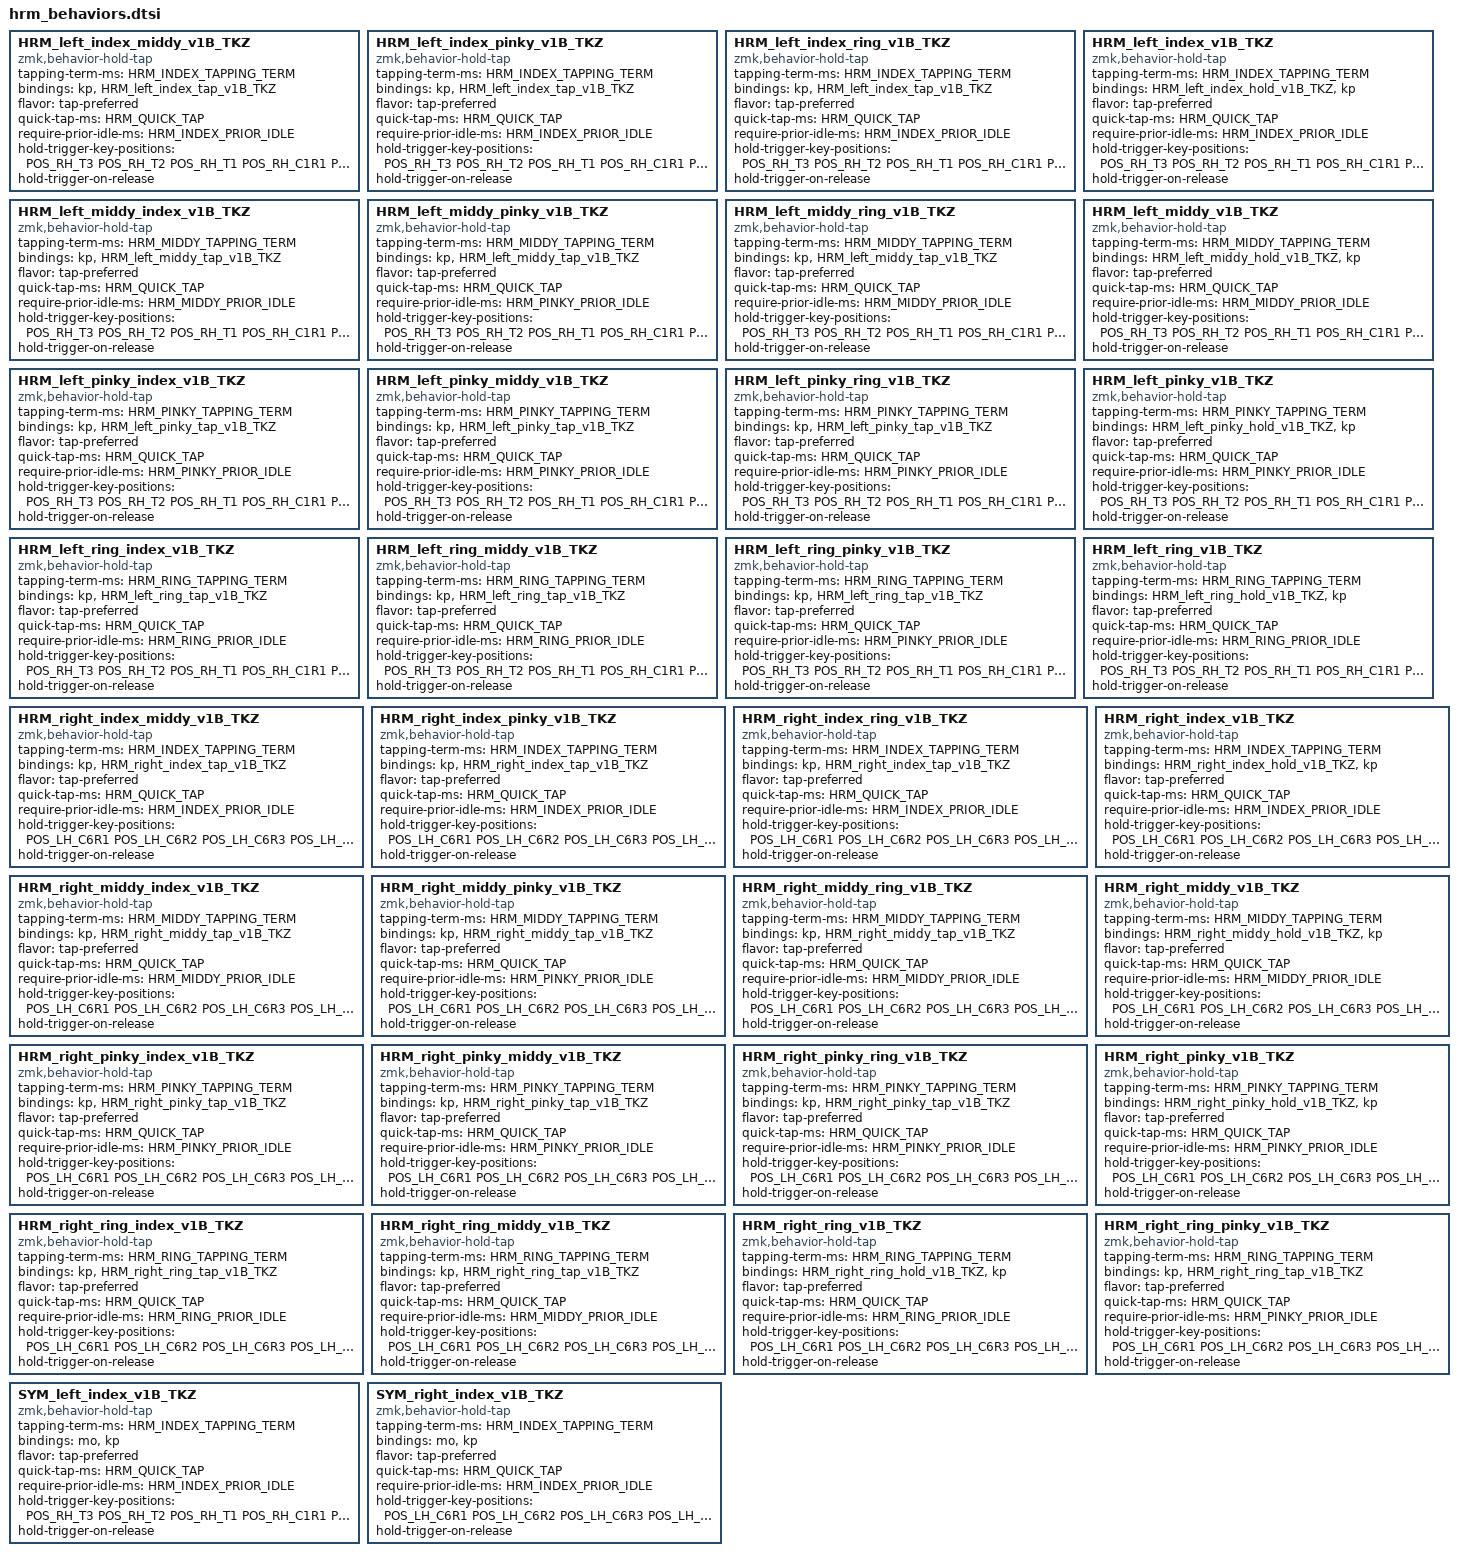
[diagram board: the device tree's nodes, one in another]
        // HRM_left_index_middy_bilateral -> &kp - &HRM_left_index_tap - TailorKey
        HRM_left_index_middy_v1B_TKZ: HRM_left_index_middy_v1B_TKZ {
            compatible = "zmk,behavior-hold-tap";
            #binding-cells = <2>;
            tapping-term-ms = <HRM_INDEX_TAPPING_TERM>;
            bindings = <&kp>, <&HRM_left_index_tap_v1B_TKZ>;
            flavor = "tap-preferred";
            quick-tap-ms = <HRM_QUICK_TAP>;
            require-prior-idle-ms = <HRM_INDEX_PRIOR_IDLE>;
            hold-trigger-key-positions = <POS_RH_T3 POS_RH_T2 POS_RH_T1 POS_RH_C1R1 POS_RH_C2R1 POS_RH_C3R1 POS_RH_C4R1 POS_RH_C5R1 POS_RH_C1R2 POS_RH_C2R2 POS_RH_C3R2 POS_RH_C4R2 POS_RH_C5R2 POS_RH_C1R3 POS_RH_C2R3 POS_RH_C3R3 POS_RH_C4R3 POS_RH_C5R3 POS_RH_C1R4 POS_RH_C2R4 POS_RH_C3R4 POS_RH_C4R4 POS_RH_C5R4 POS_RH_C2R5 POS_RH_C3R5 POS_RH_C4R5 POS_RH_C6R1 POS_RH_C6R2 POS_RH_C6R3 POS_RH_C6R4 POS_LH_T2 POS_LH_T3 POS_LH_T1>;
            hold-trigger-on-release;
        };

        // HRM_left_index_pinky_bilateral -> &kp - &HRM_left_index_tap - TailorKey
        HRM_left_index_pinky_v1B_TKZ: HRM_left_index_pinky_v1B_TKZ {
            compatible = "zmk,behavior-hold-tap";
            #binding-cells = <2>;
            tapping-term-ms = <HRM_INDEX_TAPPING_TERM>;
            bindings = <&kp>, <&HRM_left_index_tap_v1B_TKZ>;
            flavor = "tap-preferred";
            quick-tap-ms = <HRM_QUICK_TAP>;
            require-prior-idle-ms = <HRM_INDEX_PRIOR_IDLE>;
            hold-trigger-key-positions = <POS_RH_T3 POS_RH_T2 POS_RH_T1 POS_RH_C1R1 POS_RH_C2R1 POS_RH_C3R1 POS_RH_C4R1 POS_RH_C5R1 POS_RH_C1R2 POS_RH_C2R2 POS_RH_C3R2 POS_RH_C4R2 POS_RH_C5R2 POS_RH_C1R3 POS_RH_C2R3 POS_RH_C3R3 POS_RH_C4R3 POS_RH_C5R3 POS_RH_C1R4 POS_RH_C2R4 POS_RH_C3R4 POS_RH_C4R4 POS_RH_C5R4 POS_RH_C2R5 POS_RH_C3R5 POS_RH_C4R5 POS_RH_C6R1 POS_RH_C6R2 POS_RH_C6R3 POS_RH_C6R4 POS_LH_T2 POS_LH_T3 POS_LH_T1>;
            hold-trigger-on-release;
        };

        // HRM_left_index_ring_bilateral -> &kp - &HRM_left_index_tap - TailorKey
        HRM_left_index_ring_v1B_TKZ: HRM_left_index_ring_v1B_TKZ {
            compatible = "zmk,behavior-hold-tap";
            #binding-cells = <2>;
            tapping-term-ms = <HRM_INDEX_TAPPING_TERM>;
            bindings = <&kp>, <&HRM_left_index_tap_v1B_TKZ>;
            flavor = "tap-preferred";
            quick-tap-ms = <HRM_QUICK_TAP>;
            require-prior-idle-ms = <HRM_INDEX_PRIOR_IDLE>;
            hold-trigger-key-positions = <POS_RH_T3 POS_RH_T2 POS_RH_T1 POS_RH_C1R1 POS_RH_C2R1 POS_RH_C3R1 POS_RH_C4R1 POS_RH_C5R1 POS_RH_C1R2 POS_RH_C2R2 POS_RH_C3R2 POS_RH_C4R2 POS_RH_C5R2 POS_RH_C1R3 POS_RH_C2R3 POS_RH_C3R3 POS_RH_C4R3 POS_RH_C5R3 POS_RH_C1R4 POS_RH_C2R4 POS_RH_C3R4 POS_RH_C4R4 POS_RH_C5R4 POS_RH_C2R5 POS_RH_C3R5 POS_RH_C4R5 POS_RH_C6R1 POS_RH_C6R2 POS_RH_C6R3 POS_RH_C6R4 POS_LH_T2 POS_LH_T3 POS_LH_T1>;
            hold-trigger-on-release;
        };

        // HRM_left_index_bilateral -> &HRM_left_index_hold -> &kp - TailorKey
        HRM_left_index_v1B_TKZ: HRM_left_index_v1B_TKZ {
            compatible = "zmk,behavior-hold-tap";
            #binding-cells = <2>;
            tapping-term-ms = <HRM_INDEX_TAPPING_TERM>;
            bindings = <&HRM_left_index_hold_v1B_TKZ>, <&kp>;
            flavor = "tap-preferred";
            quick-tap-ms = <HRM_QUICK_TAP>;
            require-prior-idle-ms = <HRM_INDEX_PRIOR_IDLE>;
            hold-trigger-key-positions = <POS_RH_T3 POS_RH_T2 POS_RH_T1 POS_RH_C1R1 POS_RH_C2R1 POS_RH_C3R1 POS_RH_C4R1 POS_RH_C5R1 POS_RH_C1R2 POS_RH_C2R2 POS_RH_C3R2 POS_RH_C4R2 POS_RH_C5R2 POS_RH_C1R3 POS_RH_C2R3 POS_RH_C3R3 POS_RH_C4R3 POS_RH_C5R3 POS_RH_C1R4 POS_RH_C2R4 POS_RH_C3R4 POS_RH_C4R4 POS_RH_C5R4 POS_RH_C2R5 POS_RH_C3R5 POS_RH_C4R5 POS_RH_C6R1 POS_RH_C6R2 POS_RH_C6R3 POS_RH_C6R4 POS_LH_T2 POS_LH_T3 POS_LH_T1>;
            hold-trigger-on-release;
        };

        // HRM_left_middy_index_bilateral  -> &kp ->&HRM_left_middy_tap - TailorKey
        HRM_left_middy_index_v1B_TKZ: HRM_left_middy_index_v1B_TKZ {
            compatible = "zmk,behavior-hold-tap";
            #binding-cells = <2>;
            tapping-term-ms = <HRM_MIDDY_TAPPING_TERM>;
            bindings = <&kp>, <&HRM_left_middy_tap_v1B_TKZ>;
            flavor = "tap-preferred";
            quick-tap-ms = <HRM_QUICK_TAP>;
            require-prior-idle-ms = <HRM_MIDDY_PRIOR_IDLE>;
            hold-trigger-key-positions = <POS_RH_T3 POS_RH_T2 POS_RH_T1 POS_RH_C1R1 POS_RH_C2R1 POS_RH_C3R1 POS_RH_C4R1 POS_RH_C5R1 POS_RH_C1R2 POS_RH_C2R2 POS_RH_C3R2 POS_RH_C4R2 POS_RH_C5R2 POS_RH_C1R3 POS_RH_C2R3 POS_RH_C3R3 POS_RH_C4R3 POS_RH_C5R3 POS_RH_C1R4 POS_RH_C2R4 POS_RH_C3R4 POS_RH_C4R4 POS_RH_C5R4 POS_RH_C2R5 POS_RH_C3R5 POS_RH_C4R5 POS_RH_C6R1 POS_RH_C6R2 POS_RH_C6R3 POS_RH_C6R4 POS_LH_T2 POS_LH_T3 POS_LH_T1>;
            hold-trigger-on-release;
        };

        // HRM_left_middy_pinky_bilateral -> &kp - &HRM_left_pinky_tap - TailorKey
        HRM_left_middy_pinky_v1B_TKZ: HRM_left_middy_pinky_v1B_TKZ {
            compatible = "zmk,behavior-hold-tap";
            #binding-cells = <2>;
            tapping-term-ms = <HRM_MIDDY_TAPPING_TERM>;
            bindings = <&kp>, <&HRM_left_middy_tap_v1B_TKZ>;
            flavor = "tap-preferred";
            quick-tap-ms = <HRM_QUICK_TAP>;
            require-prior-idle-ms = <HRM_PINKY_PRIOR_IDLE>;
            hold-trigger-key-positions = <POS_RH_T3 POS_RH_T2 POS_RH_T1 POS_RH_C1R1 POS_RH_C2R1 POS_RH_C3R1 POS_RH_C4R1 POS_RH_C5R1 POS_RH_C1R2 POS_RH_C2R2 POS_RH_C3R2 POS_RH_C4R2 POS_RH_C5R2 POS_RH_C1R3 POS_RH_C2R3 POS_RH_C3R3 POS_RH_C4R3 POS_RH_C5R3 POS_RH_C1R4 POS_RH_C2R4 POS_RH_C3R4 POS_RH_C4R4 POS_RH_C5R4 POS_RH_C2R5 POS_RH_C3R5 POS_RH_C4R5 POS_RH_C6R1 POS_RH_C6R2 POS_RH_C6R3 POS_RH_C6R4 POS_LH_T2 POS_LH_T3 POS_LH_T1>;
            hold-trigger-on-release;
        };

        // HRM_left_middy_ring_bilateral -> &kp - &HRM_left_middy_tap - TailorKey
        HRM_left_middy_ring_v1B_TKZ: HRM_left_middy_ring_v1B_TKZ {
            compatible = "zmk,behavior-hold-tap";
            #binding-cells = <2>;
            tapping-term-ms = <HRM_MIDDY_TAPPING_TERM>;
            bindings = <&kp>, <&HRM_left_middy_tap_v1B_TKZ>;
            flavor = "tap-preferred";
            quick-tap-ms = <HRM_QUICK_TAP>;
            require-prior-idle-ms = <HRM_MIDDY_PRIOR_IDLE>;
            hold-trigger-key-positions = <POS_RH_T3 POS_RH_T2 POS_RH_T1 POS_RH_C1R1 POS_RH_C2R1 POS_RH_C3R1 POS_RH_C4R1 POS_RH_C5R1 POS_RH_C1R2 POS_RH_C2R2 POS_RH_C3R2 POS_RH_C4R2 POS_RH_C5R2 POS_RH_C1R3 POS_RH_C2R3 POS_RH_C3R3 POS_RH_C4R3 POS_RH_C5R3 POS_RH_C1R4 POS_RH_C2R4 POS_RH_C3R4 POS_RH_C4R4 POS_RH_C5R4 POS_RH_C2R5 POS_RH_C3R5 POS_RH_C4R5 POS_RH_C6R1 POS_RH_C6R2 POS_RH_C6R3 POS_RH_C6R4 POS_LH_T2 POS_LH_T3 POS_LH_T1>;
            hold-trigger-on-release;
        };

        // HRM_left_middy_bilateral -> &HRM_left_index_hold -> &kp - TailorKey
        HRM_left_middy_v1B_TKZ: HRM_left_middy_v1B_TKZ {
            compatible = "zmk,behavior-hold-tap";
            #binding-cells = <2>;
            tapping-term-ms = <HRM_MIDDY_TAPPING_TERM>;
            bindings = <&HRM_left_middy_hold_v1B_TKZ>, <&kp>;
            flavor = "tap-preferred";
            quick-tap-ms = <HRM_QUICK_TAP>;
            require-prior-idle-ms = <HRM_MIDDY_PRIOR_IDLE>;
            hold-trigger-key-positions = <POS_RH_T3 POS_RH_T2 POS_RH_T1 POS_RH_C1R1 POS_RH_C2R1 POS_RH_C3R1 POS_RH_C4R1 POS_RH_C5R1 POS_RH_C1R2 POS_RH_C2R2 POS_RH_C3R2 POS_RH_C4R2 POS_RH_C5R2 POS_RH_C1R3 POS_RH_C2R3 POS_RH_C3R3 POS_RH_C4R3 POS_RH_C5R3 POS_RH_C1R4 POS_RH_C2R4 POS_RH_C3R4 POS_RH_C4R4 POS_RH_C5R4 POS_RH_C2R5 POS_RH_C3R5 POS_RH_C4R5 POS_RH_C6R1 POS_RH_C6R2 POS_RH_C6R3 POS_RH_C6R4 POS_LH_T2 POS_LH_T3 POS_LH_T1>;
            hold-trigger-on-release;
        };

        // HRM_left_pinky_index_bilateral  -> &kp ->&HRM_left_pinky_tap - TailorKey
        HRM_left_pinky_index_v1B_TKZ: HRM_left_pinky_index_v1B_TKZ {
            compatible = "zmk,behavior-hold-tap";
            #binding-cells = <2>;
            tapping-term-ms = <HRM_PINKY_TAPPING_TERM>;
            bindings = <&kp>, <&HRM_left_pinky_tap_v1B_TKZ>;
            flavor = "tap-preferred";
            quick-tap-ms = <HRM_QUICK_TAP>;
            require-prior-idle-ms = <HRM_PINKY_PRIOR_IDLE>;
            hold-trigger-key-positions = <POS_RH_T3 POS_RH_T2 POS_RH_T1 POS_RH_C1R1 POS_RH_C2R1 POS_RH_C3R1 POS_RH_C4R1 POS_RH_C5R1 POS_RH_C1R2 POS_RH_C2R2 POS_RH_C3R2 POS_RH_C4R2 POS_RH_C5R2 POS_RH_C1R3 POS_RH_C2R3 POS_RH_C3R3 POS_RH_C4R3 POS_RH_C5R3 POS_RH_C1R4 POS_RH_C2R4 POS_RH_C3R4 POS_RH_C4R4 POS_RH_C5R4 POS_RH_C2R5 POS_RH_C3R5 POS_RH_C4R5 POS_RH_C6R1 POS_RH_C6R2 POS_RH_C6R3 POS_RH_C6R4 POS_LH_T2 POS_LH_T3 POS_LH_T1>;
            hold-trigger-on-release;
        };

        // HRM_left_pinky_middy_bilateral -> &kp - &HRM_left_pinky_tap - TailorKey
        HRM_left_pinky_middy_v1B_TKZ: HRM_left_pinky_middy_v1B_TKZ {
            compatible = "zmk,behavior-hold-tap";
            #binding-cells = <2>;
            tapping-term-ms = <HRM_PINKY_TAPPING_TERM>;
            bindings = <&kp>, <&HRM_left_pinky_tap_v1B_TKZ>;
            flavor = "tap-preferred";
            quick-tap-ms = <HRM_QUICK_TAP>;
            require-prior-idle-ms = <HRM_PINKY_PRIOR_IDLE>;
            hold-trigger-key-positions = <POS_RH_T3 POS_RH_T2 POS_RH_T1 POS_RH_C1R1 POS_RH_C2R1 POS_RH_C3R1 POS_RH_C4R1 POS_RH_C5R1 POS_RH_C1R2 POS_RH_C2R2 POS_RH_C3R2 POS_RH_C4R2 POS_RH_C5R2 POS_RH_C1R3 POS_RH_C2R3 POS_RH_C3R3 POS_RH_C4R3 POS_RH_C5R3 POS_RH_C1R4 POS_RH_C2R4 POS_RH_C3R4 POS_RH_C4R4 POS_RH_C5R4 POS_RH_C2R5 POS_RH_C3R5 POS_RH_C4R5 POS_RH_C6R1 POS_RH_C6R2 POS_RH_C6R3 POS_RH_C6R4 POS_LH_T2 POS_LH_T3 POS_LH_T1>;
            hold-trigger-on-release;
        };

        // HRM_left_pinky_ring_bilateral -> &kp - &HRM_left_pinky_tap - TailorKey
        HRM_left_pinky_ring_v1B_TKZ: HRM_left_pinky_ring_v1B_TKZ {
            compatible = "zmk,behavior-hold-tap";
            #binding-cells = <2>;
            tapping-term-ms = <HRM_PINKY_TAPPING_TERM>;
            bindings = <&kp>, <&HRM_left_pinky_tap_v1B_TKZ>;
            flavor = "tap-preferred";
            quick-tap-ms = <HRM_QUICK_TAP>;
            require-prior-idle-ms = <HRM_PINKY_PRIOR_IDLE>;
            hold-trigger-key-positions = <POS_RH_T3 POS_RH_T2 POS_RH_T1 POS_RH_C1R1 POS_RH_C2R1 POS_RH_C3R1 POS_RH_C4R1 POS_RH_C5R1 POS_RH_C1R2 POS_RH_C2R2 POS_RH_C3R2 POS_RH_C4R2 POS_RH_C5R2 POS_RH_C1R3 POS_RH_C2R3 POS_RH_C3R3 POS_RH_C4R3 POS_RH_C5R3 POS_RH_C1R4 POS_RH_C2R4 POS_RH_C3R4 POS_RH_C4R4 POS_RH_C5R4 POS_RH_C2R5 POS_RH_C3R5 POS_RH_C4R5 POS_RH_C6R1 POS_RH_C6R2 POS_RH_C6R3 POS_RH_C6R4 POS_LH_T2 POS_LH_T3 POS_LH_T1>;
            hold-trigger-on-release;
        };

        // HRM_left_pinky_bilateral  - &HRM_left_pinky_hold -> &kp - TailorKey
        HRM_left_pinky_v1B_TKZ: HRM_left_pinky_v1B_TKZ {
            compatible = "zmk,behavior-hold-tap";
            #binding-cells = <2>;
            tapping-term-ms = <HRM_PINKY_TAPPING_TERM>;
            bindings = <&HRM_left_pinky_hold_v1B_TKZ>, <&kp>;
            flavor = "tap-preferred";
            quick-tap-ms = <HRM_QUICK_TAP>;
            require-prior-idle-ms = <HRM_PINKY_PRIOR_IDLE>;
            hold-trigger-key-positions = <POS_RH_T3 POS_RH_T2 POS_RH_T1 POS_RH_C1R1 POS_RH_C2R1 POS_RH_C3R1 POS_RH_C4R1 POS_RH_C5R1 POS_RH_C1R2 POS_RH_C2R2 POS_RH_C3R2 POS_RH_C4R2 POS_RH_C5R2 POS_RH_C1R3 POS_RH_C2R3 POS_RH_C3R3 POS_RH_C4R3 POS_RH_C5R3 POS_RH_C1R4 POS_RH_C2R4 POS_RH_C3R4 POS_RH_C4R4 POS_RH_C5R4 POS_RH_C2R5 POS_RH_C3R5 POS_RH_C4R5 POS_RH_C6R1 POS_RH_C6R2 POS_RH_C6R3 POS_RH_C6R4 POS_LH_T2 POS_LH_T3 POS_LH_T1>;
            hold-trigger-on-release;
        };

        // HRM_left_ring_index_bilateral  -> &kp ->&HRM_left_ring_tap - TailorKey
        HRM_left_ring_index_v1B_TKZ: HRM_left_ring_index_v1B_TKZ {
            compatible = "zmk,behavior-hold-tap";
            #binding-cells = <2>;
            tapping-term-ms = <HRM_RING_TAPPING_TERM>;
            bindings = <&kp>, <&HRM_left_ring_tap_v1B_TKZ>;
            flavor = "tap-preferred";
            quick-tap-ms = <HRM_QUICK_TAP>;
            require-prior-idle-ms = <HRM_RING_PRIOR_IDLE>;
            hold-trigger-key-positions = <POS_RH_T3 POS_RH_T2 POS_RH_T1 POS_RH_C1R1 POS_RH_C2R1 POS_RH_C3R1 POS_RH_C4R1 POS_RH_C5R1 POS_RH_C1R2 POS_RH_C2R2 POS_RH_C3R2 POS_RH_C4R2 POS_RH_C5R2 POS_RH_C1R3 POS_RH_C2R3 POS_RH_C3R3 POS_RH_C4R3 POS_RH_C5R3 POS_RH_C1R4 POS_RH_C2R4 POS_RH_C3R4 POS_RH_C4R4 POS_RH_C5R4 POS_RH_C2R5 POS_RH_C3R5 POS_RH_C4R5 POS_RH_C6R1 POS_RH_C6R2 POS_RH_C6R3 POS_RH_C6R4 POS_LH_T2 POS_LH_T3 POS_LH_T1>;
            hold-trigger-on-release;
        };

        // HRM_left_ring_middy_bilateral -> &kp - &HRM_left_ring_tap - TailorKey
        HRM_left_ring_middy_v1B_TKZ: HRM_left_ring_middy_v1B_TKZ {
            compatible = "zmk,behavior-hold-tap";
            #binding-cells = <2>;
            tapping-term-ms = <HRM_RING_TAPPING_TERM>;
            bindings = <&kp>, <&HRM_left_ring_tap_v1B_TKZ>;
            flavor = "tap-preferred";
            quick-tap-ms = <HRM_QUICK_TAP>;
            require-prior-idle-ms = <HRM_RING_PRIOR_IDLE>;
            hold-trigger-key-positions = <POS_RH_T3 POS_RH_T2 POS_RH_T1 POS_RH_C1R1 POS_RH_C2R1 POS_RH_C3R1 POS_RH_C4R1 POS_RH_C5R1 POS_RH_C1R2 POS_RH_C2R2 POS_RH_C3R2 POS_RH_C4R2 POS_RH_C5R2 POS_RH_C1R3 POS_RH_C2R3 POS_RH_C3R3 POS_RH_C4R3 POS_RH_C5R3 POS_RH_C1R4 POS_RH_C2R4 POS_RH_C3R4 POS_RH_C4R4 POS_RH_C5R4 POS_RH_C2R5 POS_RH_C3R5 POS_RH_C4R5 POS_RH_C6R1 POS_RH_C6R2 POS_RH_C6R3 POS_RH_C6R4 POS_LH_T2 POS_LH_T3 POS_LH_T1>;
            hold-trigger-on-release;
        };

        // HRM_left_ring_pinky_bilateral -> &kp - &HRM_left_ring_tap - TailorKey
        HRM_left_ring_pinky_v1B_TKZ: HRM_left_ring_pinky_v1B_TKZ {
            compatible = "zmk,behavior-hold-tap";
            #binding-cells = <2>;
            tapping-term-ms = <HRM_RING_TAPPING_TERM>;
            bindings = <&kp>, <&HRM_left_ring_tap_v1B_TKZ>;
            flavor = "tap-preferred";
            quick-tap-ms = <HRM_QUICK_TAP>;
            require-prior-idle-ms = <HRM_PINKY_PRIOR_IDLE>;
            hold-trigger-key-positions = <POS_RH_T3 POS_RH_T2 POS_RH_T1 POS_RH_C1R1 POS_RH_C2R1 POS_RH_C3R1 POS_RH_C4R1 POS_RH_C5R1 POS_RH_C1R2 POS_RH_C2R2 POS_RH_C3R2 POS_RH_C4R2 POS_RH_C5R2 POS_RH_C1R3 POS_RH_C2R3 POS_RH_C3R3 POS_RH_C4R3 POS_RH_C5R3 POS_RH_C1R4 POS_RH_C2R4 POS_RH_C3R4 POS_RH_C4R4 POS_RH_C5R4 POS_RH_C2R5 POS_RH_C3R5 POS_RH_C4R5 POS_RH_C6R1 POS_RH_C6R2 POS_RH_C6R3 POS_RH_C6R4 POS_LH_T2 POS_LH_T3 POS_LH_T1>;
            hold-trigger-on-release;
        };

        // HRM_left_ring_bilateral  - &HRM_left_ring_hold -> &kp - TailorKey
        HRM_left_ring_v1B_TKZ: HRM_left_ring_v1B_TKZ {
            compatible = "zmk,behavior-hold-tap";
            #binding-cells = <2>;
            tapping-term-ms = <HRM_RING_TAPPING_TERM>;
            bindings = <&HRM_left_ring_hold_v1B_TKZ>, <&kp>;
            flavor = "tap-preferred";
            quick-tap-ms = <HRM_QUICK_TAP>;
            require-prior-idle-ms = <HRM_RING_PRIOR_IDLE>;
            hold-trigger-key-positions = <POS_RH_T3 POS_RH_T2 POS_RH_T1 POS_RH_C1R1 POS_RH_C2R1 POS_RH_C3R1 POS_RH_C4R1 POS_RH_C5R1 POS_RH_C1R2 POS_RH_C2R2 POS_RH_C3R2 POS_RH_C4R2 POS_RH_C5R2 POS_RH_C1R3 POS_RH_C2R3 POS_RH_C3R3 POS_RH_C4R3 POS_RH_C5R3 POS_RH_C1R4 POS_RH_C2R4 POS_RH_C3R4 POS_RH_C4R4 POS_RH_C5R4 POS_RH_C2R5 POS_RH_C3R5 POS_RH_C4R5 POS_RH_C6R1 POS_RH_C6R2 POS_RH_C6R3 POS_RH_C6R4 POS_LH_T2 POS_LH_T3 POS_LH_T1>;
            hold-trigger-on-release;
        };

        // HRM_right_index_middy_bilateral -> &kp - &HRM_right_index_tap - TailorKey
        HRM_right_index_middy_v1B_TKZ: HRM_right_index_middy_v1B_TKZ {
            compatible = "zmk,behavior-hold-tap";
            #binding-cells = <2>;
            tapping-term-ms = <HRM_INDEX_TAPPING_TERM>;
            bindings = <&kp>, <&HRM_right_index_tap_v1B_TKZ>;
            flavor = "tap-preferred";
            quick-tap-ms = <HRM_QUICK_TAP>;
            require-prior-idle-ms = <HRM_INDEX_PRIOR_IDLE>;
            hold-trigger-key-positions = <POS_LH_C6R1 POS_LH_C6R2 POS_LH_C6R3 POS_LH_C6R4 POS_LH_C5R4 POS_LH_C5R3 POS_LH_C5R2 POS_LH_C4R1 POS_LH_C5R1 POS_LH_C4R2 POS_LH_C4R3 POS_LH_C4R4 POS_LH_C4R5 POS_LH_C3R5 POS_LH_C3R4 POS_LH_C3R3 POS_LH_C3R2 POS_LH_C3R1 POS_LH_C2R1 POS_LH_C1R1 POS_LH_C1R2 POS_LH_C2R2 POS_LH_C2R3 POS_LH_C1R3 POS_LH_C1R4 POS_LH_C2R4 POS_LH_C2R5 POS_LH_T3 POS_LH_T2 POS_LH_T1 POS_RH_T1 POS_RH_T2 POS_RH_T3>;
            hold-trigger-on-release;
        };

        // HRM_right_index_pinky_bilateral -> &kp - &HRM_right_index_tap - TailorKey
        HRM_right_index_pinky_v1B_TKZ: HRM_right_index_pinky_v1B_TKZ {
            compatible = "zmk,behavior-hold-tap";
            #binding-cells = <2>;
            tapping-term-ms = <HRM_INDEX_TAPPING_TERM>;
            bindings = <&kp>, <&HRM_right_index_tap_v1B_TKZ>;
            flavor = "tap-preferred";
            quick-tap-ms = <HRM_QUICK_TAP>;
            require-prior-idle-ms = <HRM_INDEX_PRIOR_IDLE>;
            hold-trigger-key-positions = <POS_LH_C6R1 POS_LH_C6R2 POS_LH_C6R3 POS_LH_C6R4 POS_LH_C5R4 POS_LH_C5R3 POS_LH_C5R2 POS_LH_C4R1 POS_LH_C5R1 POS_LH_C4R2 POS_LH_C4R3 POS_LH_C4R4 POS_LH_C4R5 POS_LH_C3R5 POS_LH_C3R4 POS_LH_C3R3 POS_LH_C3R2 POS_LH_C3R1 POS_LH_C2R1 POS_LH_C1R1 POS_LH_C1R2 POS_LH_C2R2 POS_LH_C2R3 POS_LH_C1R3 POS_LH_C1R4 POS_LH_C2R4 POS_LH_C2R5 POS_LH_T3 POS_LH_T2 POS_LH_T1 POS_RH_T1 POS_RH_T2 POS_RH_T3>;
            hold-trigger-on-release;
        };

        // HRM_right_index_ring_bilateral -> &kp - &HRM_right_index_tap - TailorKey
        HRM_right_index_ring_v1B_TKZ: HRM_right_index_ring_v1B_TKZ {
            compatible = "zmk,behavior-hold-tap";
            #binding-cells = <2>;
            tapping-term-ms = <HRM_INDEX_TAPPING_TERM>;
            bindings = <&kp>, <&HRM_right_index_tap_v1B_TKZ>;
            flavor = "tap-preferred";
            quick-tap-ms = <HRM_QUICK_TAP>;
            require-prior-idle-ms = <HRM_INDEX_PRIOR_IDLE>;
            hold-trigger-key-positions = <POS_LH_C6R1 POS_LH_C6R2 POS_LH_C6R3 POS_LH_C6R4 POS_LH_C5R4 POS_LH_C5R3 POS_LH_C5R2 POS_LH_C4R1 POS_LH_C5R1 POS_LH_C4R2 POS_LH_C4R3 POS_LH_C4R4 POS_LH_C4R5 POS_LH_C3R5 POS_LH_C3R4 POS_LH_C3R3 POS_LH_C3R2 POS_LH_C3R1 POS_LH_C2R1 POS_LH_C1R1 POS_LH_C1R2 POS_LH_C2R2 POS_LH_C2R3 POS_LH_C1R3 POS_LH_C1R4 POS_LH_C2R4 POS_LH_C2R5 POS_LH_T3 POS_LH_T2 POS_LH_T1 POS_RH_T1 POS_RH_T2 POS_RH_T3>;
            hold-trigger-on-release;
        };

        // HRM_right_index_bilateral -> &HRM_right_index_hold -> &kp - TailorKey
        HRM_right_index_v1B_TKZ: HRM_right_index_v1B_TKZ {
            compatible = "zmk,behavior-hold-tap";
            #binding-cells = <2>;
            tapping-term-ms = <HRM_INDEX_TAPPING_TERM>;
            bindings = <&HRM_right_index_hold_v1B_TKZ>, <&kp>;
            flavor = "tap-preferred";
            quick-tap-ms = <HRM_QUICK_TAP>;
            require-prior-idle-ms = <HRM_INDEX_PRIOR_IDLE>;
            hold-trigger-key-positions = <POS_LH_C6R1 POS_LH_C6R2 POS_LH_C6R3 POS_LH_C6R4 POS_LH_C5R4 POS_LH_C5R3 POS_LH_C5R2 POS_LH_C4R1 POS_LH_C5R1 POS_LH_C4R2 POS_LH_C4R3 POS_LH_C4R4 POS_LH_C4R5 POS_LH_C3R5 POS_LH_C3R4 POS_LH_C3R3 POS_LH_C3R2 POS_LH_C3R1 POS_LH_C2R1 POS_LH_C1R1 POS_LH_C1R2 POS_LH_C2R2 POS_LH_C2R3 POS_LH_C1R3 POS_LH_C1R4 POS_LH_C2R4 POS_LH_C2R5 POS_LH_T3 POS_LH_T2 POS_LH_T1 POS_RH_T1 POS_RH_T2 POS_RH_T3>;
            hold-trigger-on-release;
        };

        // HRM_right_middy_index_bilateral  -> &kp ->&HRM_right_middy_tap - TailorKey
        HRM_right_middy_index_v1B_TKZ: HRM_right_middy_index_v1B_TKZ {
            compatible = "zmk,behavior-hold-tap";
            #binding-cells = <2>;
            tapping-term-ms = <HRM_MIDDY_TAPPING_TERM>;
            bindings = <&kp>, <&HRM_right_middy_tap_v1B_TKZ>;
            flavor = "tap-preferred";
            quick-tap-ms = <HRM_QUICK_TAP>;
            require-prior-idle-ms = <HRM_MIDDY_PRIOR_IDLE>;
            hold-trigger-key-positions = <POS_LH_C6R1 POS_LH_C6R2 POS_LH_C6R3 POS_LH_C6R4 POS_LH_C5R4 POS_LH_C5R3 POS_LH_C5R2 POS_LH_C4R1 POS_LH_C5R1 POS_LH_C4R2 POS_LH_C4R3 POS_LH_C4R4 POS_LH_C4R5 POS_LH_C3R5 POS_LH_C3R4 POS_LH_C3R3 POS_LH_C3R2 POS_LH_C3R1 POS_LH_C2R1 POS_LH_C1R1 POS_LH_C1R2 POS_LH_C2R2 POS_LH_C2R3 POS_LH_C1R3 POS_LH_C1R4 POS_LH_C2R4 POS_LH_C2R5 POS_LH_T3 POS_LH_T2 POS_LH_T1 POS_RH_T1 POS_RH_T2 POS_RH_T3>;
            hold-trigger-on-release;
        };

        // HRM_right_middy_pinky_bilateral -> &kp - &HRM_right_pinky_tap - TailorKey
        HRM_right_middy_pinky_v1B_TKZ: HRM_right_middy_pinky_v1B_TKZ {
            compatible = "zmk,behavior-hold-tap";
            #binding-cells = <2>;
            tapping-term-ms = <HRM_MIDDY_TAPPING_TERM>;
            bindings = <&kp>, <&HRM_right_middy_tap_v1B_TKZ>;
            flavor = "tap-preferred";
            quick-tap-ms = <HRM_QUICK_TAP>;
            require-prior-idle-ms = <HRM_PINKY_PRIOR_IDLE>;
            hold-trigger-key-positions = <POS_LH_C6R1 POS_LH_C6R2 POS_LH_C6R3 POS_LH_C6R4 POS_LH_C5R4 POS_LH_C5R3 POS_LH_C5R2 POS_LH_C4R1 POS_LH_C5R1 POS_LH_C4R2 POS_LH_C4R3 POS_LH_C4R4 POS_LH_C4R5 POS_LH_C3R5 POS_LH_C3R4 POS_LH_C3R3 POS_LH_C3R2 POS_LH_C3R1 POS_LH_C2R1 POS_LH_C1R1 POS_LH_C1R2 POS_LH_C2R2 POS_LH_C2R3 POS_LH_C1R3 POS_LH_C1R4 POS_LH_C2R4 POS_LH_C2R5 POS_LH_T3 POS_LH_T2 POS_LH_T1 POS_RH_T1 POS_RH_T2 POS_RH_T3>;
            hold-trigger-on-release;
        };

        // HRM_right_middy_ring_bilateral -> &kp - &HRM_right_middy_tap - TailorKey
        HRM_right_middy_ring_v1B_TKZ: HRM_right_middy_ring_v1B_TKZ {
            compatible = "zmk,behavior-hold-tap";
            #binding-cells = <2>;
            tapping-term-ms = <HRM_MIDDY_TAPPING_TERM>;
            bindings = <&kp>, <&HRM_right_middy_tap_v1B_TKZ>;
            flavor = "tap-preferred";
            quick-tap-ms = <HRM_QUICK_TAP>;
            require-prior-idle-ms = <HRM_MIDDY_PRIOR_IDLE>;
            hold-trigger-key-positions = <POS_LH_C6R1 POS_LH_C6R2 POS_LH_C6R3 POS_LH_C6R4 POS_LH_C5R4 POS_LH_C5R3 POS_LH_C5R2 POS_LH_C4R1 POS_LH_C5R1 POS_LH_C4R2 POS_LH_C4R3 POS_LH_C4R4 POS_LH_C4R5 POS_LH_C3R5 POS_LH_C3R4 POS_LH_C3R3 POS_LH_C3R2 POS_LH_C3R1 POS_LH_C2R1 POS_LH_C1R1 POS_LH_C1R2 POS_LH_C2R2 POS_LH_C2R3 POS_LH_C1R3 POS_LH_C1R4 POS_LH_C2R4 POS_LH_C2R5 POS_LH_T3 POS_LH_T2 POS_LH_T1 POS_RH_T1 POS_RH_T2 POS_RH_T3>;
            hold-trigger-on-release;
        };

        // HRM_right_middy_bilateral -> &HRM_right_index_hold -> &kp - TailorKey
        HRM_right_middy_v1B_TKZ: HRM_right_middy_v1B_TKZ {
            compatible = "zmk,behavior-hold-tap";
            #binding-cells = <2>;
            tapping-term-ms = <HRM_MIDDY_TAPPING_TERM>;
            bindings = <&HRM_right_middy_hold_v1B_TKZ>, <&kp>;
            flavor = "tap-preferred";
            quick-tap-ms = <HRM_QUICK_TAP>;
            require-prior-idle-ms = <HRM_MIDDY_PRIOR_IDLE>;
            hold-trigger-key-positions = <POS_LH_C6R1 POS_LH_C6R2 POS_LH_C6R3 POS_LH_C6R4 POS_LH_C5R4 POS_LH_C5R3 POS_LH_C5R2 POS_LH_C4R1 POS_LH_C5R1 POS_LH_C4R2 POS_LH_C4R3 POS_LH_C4R4 POS_LH_C4R5 POS_LH_C3R5 POS_LH_C3R4 POS_LH_C3R3 POS_LH_C3R2 POS_LH_C3R1 POS_LH_C2R1 POS_LH_C1R1 POS_LH_C1R2 POS_LH_C2R2 POS_LH_C2R3 POS_LH_C1R3 POS_LH_C1R4 POS_LH_C2R4 POS_LH_C2R5 POS_LH_T3 POS_LH_T2 POS_LH_T1 POS_RH_T1 POS_RH_T2 POS_RH_T3>;
            hold-trigger-on-release;
        };

        // HRM_right_pinky_index_bilateral  -> &kp ->&HRM_right_pinky_tap - TailorKey
        HRM_right_pinky_index_v1B_TKZ: HRM_right_pinky_index_v1B_TKZ {
            compatible = "zmk,behavior-hold-tap";
            #binding-cells = <2>;
            tapping-term-ms = <HRM_PINKY_TAPPING_TERM>;
            bindings = <&kp>, <&HRM_right_pinky_tap_v1B_TKZ>;
            flavor = "tap-preferred";
            quick-tap-ms = <HRM_QUICK_TAP>;
            require-prior-idle-ms = <HRM_PINKY_PRIOR_IDLE>;
            hold-trigger-key-positions = <POS_LH_C6R1 POS_LH_C6R2 POS_LH_C6R3 POS_LH_C6R4 POS_LH_C5R4 POS_LH_C5R3 POS_LH_C5R2 POS_LH_C4R1 POS_LH_C5R1 POS_LH_C4R2 POS_LH_C4R3 POS_LH_C4R4 POS_LH_C4R5 POS_LH_C3R5 POS_LH_C3R4 POS_LH_C3R3 POS_LH_C3R2 POS_LH_C3R1 POS_LH_C2R1 POS_LH_C1R1 POS_LH_C1R2 POS_LH_C2R2 POS_LH_C2R3 POS_LH_C1R3 POS_LH_C1R4 POS_LH_C2R4 POS_LH_C2R5 POS_LH_T3 POS_LH_T2 POS_LH_T1 POS_RH_T1 POS_RH_T2 POS_RH_T3>;
            hold-trigger-on-release;
        };

        // HRM_right_pinky_middy_bilateral -> &kp - &HRM_right_pinky_tap - TailorKey
        HRM_right_pinky_middy_v1B_TKZ: HRM_right_pinky_middy_v1B_TKZ {
            compatible = "zmk,behavior-hold-tap";
            #binding-cells = <2>;
            tapping-term-ms = <HRM_PINKY_TAPPING_TERM>;
            bindings = <&kp>, <&HRM_right_pinky_tap_v1B_TKZ>;
            flavor = "tap-preferred";
            quick-tap-ms = <HRM_QUICK_TAP>;
            require-prior-idle-ms = <HRM_PINKY_PRIOR_IDLE>;
            hold-trigger-key-positions = <POS_LH_C6R1 POS_LH_C6R2 POS_LH_C6R3 POS_LH_C6R4 POS_LH_C5R4 POS_LH_C5R3 POS_LH_C5R2 POS_LH_C4R1 POS_LH_C5R1 POS_LH_C4R2 POS_LH_C4R3 POS_LH_C4R4 POS_LH_C4R5 POS_LH_C3R5 POS_LH_C3R4 POS_LH_C3R3 POS_LH_C3R2 POS_LH_C3R1 POS_LH_C2R1 POS_LH_C1R1 POS_LH_C1R2 POS_LH_C2R2 POS_LH_C2R3 POS_LH_C1R3 POS_LH_C1R4 POS_LH_C2R4 POS_LH_C2R5 POS_LH_T3 POS_LH_T2 POS_LH_T1 POS_RH_T1 POS_RH_T2 POS_RH_T3>;
            hold-trigger-on-release;
        };

        // HRM_right_pinky_ring_bilateral -> &kp - &HRM_right_pinky_tap - TailorKey
        HRM_right_pinky_ring_v1B_TKZ: HRM_right_pinky_ring_v1B_TKZ {
            compatible = "zmk,behavior-hold-tap";
            #binding-cells = <2>;
            tapping-term-ms = <HRM_PINKY_TAPPING_TERM>;
            bindings = <&kp>, <&HRM_right_pinky_tap_v1B_TKZ>;
            flavor = "tap-preferred";
            quick-tap-ms = <HRM_QUICK_TAP>;
            require-prior-idle-ms = <HRM_PINKY_PRIOR_IDLE>;
            hold-trigger-key-positions = <POS_LH_C6R1 POS_LH_C6R2 POS_LH_C6R3 POS_LH_C6R4 POS_LH_C5R4 POS_LH_C5R3 POS_LH_C5R2 POS_LH_C4R1 POS_LH_C5R1 POS_LH_C4R2 POS_LH_C4R3 POS_LH_C4R4 POS_LH_C4R5 POS_LH_C3R5 POS_LH_C3R4 POS_LH_C3R3 POS_LH_C3R2 POS_LH_C3R1 POS_LH_C2R1 POS_LH_C1R1 POS_LH_C1R2 POS_LH_C2R2 POS_LH_C2R3 POS_LH_C1R3 POS_LH_C1R4 POS_LH_C2R4 POS_LH_C2R5 POS_LH_T3 POS_LH_T2 POS_LH_T1 POS_RH_T1 POS_RH_T2 POS_RH_T3>;
            hold-trigger-on-release;
        };

        // HRM_right_pinky_bilateral  - &HRM_right_pinky_hold -> &kp - TailorKey
        HRM_right_pinky_v1B_TKZ: HRM_right_pinky_v1B_TKZ {
            compatible = "zmk,behavior-hold-tap";
            #binding-cells = <2>;
            tapping-term-ms = <HRM_PINKY_TAPPING_TERM>;
            bindings = <&HRM_right_pinky_hold_v1B_TKZ>, <&kp>;
            flavor = "tap-preferred";
            quick-tap-ms = <HRM_QUICK_TAP>;
            require-prior-idle-ms = <HRM_PINKY_PRIOR_IDLE>;
            hold-trigger-key-positions = <POS_LH_C6R1 POS_LH_C6R2 POS_LH_C6R3 POS_LH_C6R4 POS_LH_C5R4 POS_LH_C5R3 POS_LH_C5R2 POS_LH_C4R1 POS_LH_C5R1 POS_LH_C4R2 POS_LH_C4R3 POS_LH_C4R4 POS_LH_C4R5 POS_LH_C3R5 POS_LH_C3R4 POS_LH_C3R3 POS_LH_C3R2 POS_LH_C3R1 POS_LH_C2R1 POS_LH_C1R1 POS_LH_C1R2 POS_LH_C2R2 POS_LH_C2R3 POS_LH_C1R3 POS_LH_C1R4 POS_LH_C2R4 POS_LH_C2R5 POS_LH_T3 POS_LH_T2 POS_LH_T1 POS_RH_T1 POS_RH_T2 POS_RH_T3>;
            hold-trigger-on-release;
        };

        // HRM_right_ring_index_bilateral  -> &kp ->&HRM_right_ring_tap - TailorKey
        HRM_right_ring_index_v1B_TKZ: HRM_right_ring_index_v1B_TKZ {
            compatible = "zmk,behavior-hold-tap";
            #binding-cells = <2>;
            tapping-term-ms = <HRM_RING_TAPPING_TERM>;
            bindings = <&kp>, <&HRM_right_ring_tap_v1B_TKZ>;
            flavor = "tap-preferred";
            quick-tap-ms = <HRM_QUICK_TAP>;
            require-prior-idle-ms = <HRM_RING_PRIOR_IDLE>;
            hold-trigger-key-positions = <POS_LH_C6R1 POS_LH_C6R2 POS_LH_C6R3 POS_LH_C6R4 POS_LH_C5R4 POS_LH_C5R3 POS_LH_C5R2 POS_LH_C4R1 POS_LH_C5R1 POS_LH_C4R2 POS_LH_C4R3 POS_LH_C4R4 POS_LH_C4R5 POS_LH_C3R5 POS_LH_C3R4 POS_LH_C3R3 POS_LH_C3R2 POS_LH_C3R1 POS_LH_C2R1 POS_LH_C1R1 POS_LH_C1R2 POS_LH_C2R2 POS_LH_C2R3 POS_LH_C1R3 POS_LH_C1R4 POS_LH_C2R4 POS_LH_C2R5 POS_LH_T3 POS_LH_T2 POS_LH_T1 POS_RH_T1 POS_RH_T2 POS_RH_T3>;
            hold-trigger-on-release;
        };

        // HRM_right_ring_middy_bilateral -> &kp - &HRM_right_ring_tap - TailorKey
        HRM_right_ring_middy_v1B_TKZ: HRM_right_ring_middy_v1B_TKZ {
            compatible = "zmk,behavior-hold-tap";
            #binding-cells = <2>;
            tapping-term-ms = <HRM_RING_TAPPING_TERM>;
            bindings = <&kp>, <&HRM_right_ring_tap_v1B_TKZ>;
            flavor = "tap-preferred";
            quick-tap-ms = <HRM_QUICK_TAP>;
            require-prior-idle-ms = <HRM_MIDDY_PRIOR_IDLE>;
            hold-trigger-key-positions = <POS_LH_C6R1 POS_LH_C6R2 POS_LH_C6R3 POS_LH_C6R4 POS_LH_C5R4 POS_LH_C5R3 POS_LH_C5R2 POS_LH_C4R1 POS_LH_C5R1 POS_LH_C4R2 POS_LH_C4R3 POS_LH_C4R4 POS_LH_C4R5 POS_LH_C3R5 POS_LH_C3R4 POS_LH_C3R3 POS_LH_C3R2 POS_LH_C3R1 POS_LH_C2R1 POS_LH_C1R1 POS_LH_C1R2 POS_LH_C2R2 POS_LH_C2R3 POS_LH_C1R3 POS_LH_C1R4 POS_LH_C2R4 POS_LH_C2R5 POS_LH_T3 POS_LH_T2 POS_LH_T1 POS_RH_T1 POS_RH_T2 POS_RH_T3>;
            hold-trigger-on-release;
        };

        // HRM_right_ring_bilateral  - &HRM_right_ring_hold -> &kp - TailorKey
        HRM_right_ring_v1B_TKZ: HRM_right_ring_v1B_TKZ {
            compatible = "zmk,behavior-hold-tap";
            #binding-cells = <2>;
            tapping-term-ms = <HRM_RING_TAPPING_TERM>;
            bindings = <&HRM_right_ring_hold_v1B_TKZ>, <&kp>;
            flavor = "tap-preferred";
            quick-tap-ms = <HRM_QUICK_TAP>;
            require-prior-idle-ms = <HRM_RING_PRIOR_IDLE>;
            hold-trigger-key-positions = <POS_LH_C6R1 POS_LH_C6R2 POS_LH_C6R3 POS_LH_C6R4 POS_LH_C5R4 POS_LH_C5R3 POS_LH_C5R2 POS_LH_C4R1 POS_LH_C5R1 POS_LH_C4R2 POS_LH_C4R3 POS_LH_C4R4 POS_LH_C4R5 POS_LH_C3R5 POS_LH_C3R4 POS_LH_C3R3 POS_LH_C3R2 POS_LH_C3R1 POS_LH_C2R1 POS_LH_C1R1 POS_LH_C1R2 POS_LH_C2R2 POS_LH_C2R3 POS_LH_C1R3 POS_LH_C1R4 POS_LH_C2R4 POS_LH_C2R5 POS_LH_T3 POS_LH_T2 POS_LH_T1 POS_RH_T1 POS_RH_T2 POS_RH_T3>;
            hold-trigger-on-release;
        };

        // HRM_right_ring_pinky_bilateral -> &kp - &HRM_right_ring_tap - TailorKey
        HRM_right_ring_pinky_v1B_TKZ: HRM_right_ring_pinky_v1B_TKZ {
            compatible = "zmk,behavior-hold-tap";
            #binding-cells = <2>;
            tapping-term-ms = <HRM_RING_TAPPING_TERM>;
            bindings = <&kp>, <&HRM_right_ring_tap_v1B_TKZ>;
            flavor = "tap-preferred";
            quick-tap-ms = <HRM_QUICK_TAP>;
            require-prior-idle-ms = <HRM_PINKY_PRIOR_IDLE>;
            hold-trigger-key-positions = <POS_LH_C6R1 POS_LH_C6R2 POS_LH_C6R3 POS_LH_C6R4 POS_LH_C5R4 POS_LH_C5R3 POS_LH_C5R2 POS_LH_C4R1 POS_LH_C5R1 POS_LH_C4R2 POS_LH_C4R3 POS_LH_C4R4 POS_LH_C4R5 POS_LH_C3R5 POS_LH_C3R4 POS_LH_C3R3 POS_LH_C3R2 POS_LH_C3R1 POS_LH_C2R1 POS_LH_C1R1 POS_LH_C1R2 POS_LH_C2R2 POS_LH_C2R3 POS_LH_C1R3 POS_LH_C1R4 POS_LH_C2R4 POS_LH_C2R5 POS_LH_T3 POS_LH_T2 POS_LH_T1 POS_RH_T1 POS_RH_T2 POS_RH_T3>;
            hold-trigger-on-release;
        };

        // SYM_left_index_bilateral -> &mo LAYER_Symbol_lh (right-hand triggered), tap for key - TailorKey
        SYM_left_index_v1B_TKZ: SYM_left_index_v1B_TKZ {
            compatible = "zmk,behavior-hold-tap";
            #binding-cells = <2>;
            tapping-term-ms = <HRM_INDEX_TAPPING_TERM>;
            bindings = <&mo>, <&kp>;
            flavor = "tap-preferred";
            quick-tap-ms = <HRM_QUICK_TAP>;
            require-prior-idle-ms = <HRM_INDEX_PRIOR_IDLE>;
            hold-trigger-key-positions = <POS_RH_T3 POS_RH_T2 POS_RH_T1 POS_RH_C1R1 POS_RH_C2R1 POS_RH_C3R1 POS_RH_C4R1 POS_RH_C5R1 POS_RH_C1R2 POS_RH_C2R2 POS_RH_C3R2 POS_RH_C4R2 POS_RH_C5R2 POS_RH_C1R3 POS_RH_C2R3 POS_RH_C3R3 POS_RH_C4R3 POS_RH_C5R3 POS_RH_C1R4 POS_RH_C2R4 POS_RH_C3R4 POS_RH_C4R4 POS_RH_C5R4 POS_RH_C2R5 POS_RH_C3R5 POS_RH_C4R5 POS_RH_C6R1 POS_RH_C6R2 POS_RH_C6R3 POS_RH_C6R4 POS_LH_T2 POS_LH_T3 POS_LH_T1>;
            hold-trigger-on-release;
        };

        // SYM_right_index_bilateral -> &mo LAYER_Symbol_rh (left-hand triggered), tap for key - TailorKey
        SYM_right_index_v1B_TKZ: SYM_right_index_v1B_TKZ {
            compatible = "zmk,behavior-hold-tap";
            #binding-cells = <2>;
            tapping-term-ms = <HRM_INDEX_TAPPING_TERM>;
            bindings = <&mo>, <&kp>;
            flavor = "tap-preferred";
            quick-tap-ms = <HRM_QUICK_TAP>;
            require-prior-idle-ms = <HRM_INDEX_PRIOR_IDLE>;
            hold-trigger-key-positions = <POS_LH_C6R1 POS_LH_C6R2 POS_LH_C6R3 POS_LH_C6R4 POS_LH_C5R4 POS_LH_C5R3 POS_LH_C5R2 POS_LH_C4R1 POS_LH_C5R1 POS_LH_C4R2 POS_LH_C4R3 POS_LH_C4R4 POS_LH_C4R5 POS_LH_C3R5 POS_LH_C3R4 POS_LH_C3R3 POS_LH_C3R2 POS_LH_C3R1 POS_LH_C2R1 POS_LH_C1R1 POS_LH_C1R2 POS_LH_C2R2 POS_LH_C2R3 POS_LH_C1R3 POS_LH_C1R4 POS_LH_C2R4 POS_LH_C2R5 POS_LH_T3 POS_LH_T2 POS_LH_T1 POS_RH_T1 POS_RH_T2 POS_RH_T3>;
            hold-trigger-on-release;
        };
